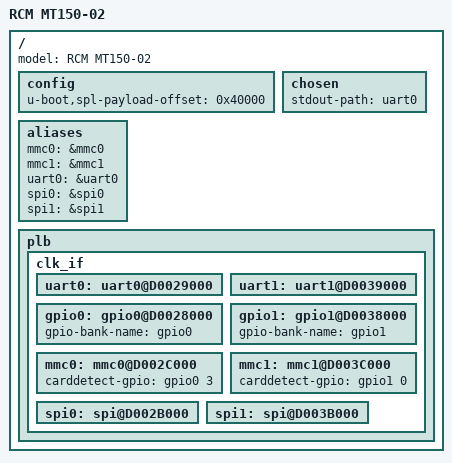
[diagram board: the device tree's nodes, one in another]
/*
 * Device Tree Source for RCM MT150.02 board
 *
 * Copyright (C) 2020 MIR
 *	Mikhail.Petrov@mir.dev
 *
 * SPDX-License-Identifier: GPL-2.0+
 */

#include "1888bm018.dtsi"

/ {
	model = "RCM MT150-02";

	config {
		u-boot,spl-payload-offset = <0x40000>;
	};

	chosen {
		stdout-path = "uart0";
	};

	aliases {
		mmc0 = &mmc0;
		mmc1 = &mmc1;
		uart0 = &uart0;
		spi0 = &spi0;
		spi1 = &spi1;
	};

	plb {
		clk_if {
			// console
			uart0: uart0@D0029000 {
				status = "okay";
			};

			uart1: uart1@D0039000 {
				status = "okay";
			};

			gpio0: gpio0@D0028000 {
				status = "okay";
				gpio-bank-name = "gpio0";
			};

			gpio1: gpio1@D0038000 {
				status = "okay";
				gpio-bank-name = "gpio1";
			};

			mmc0: mmc0@D002C000 {
				status = "okay";
				carddetect-gpio = <&gpio0 3 0>;
			};

			mmc1: mmc1@D003C000 {
				// status = "okay";
				carddetect-gpio = <&gpio1 0 0>;
			};

			spi0: spi@D002B000 {
				// status = "okay";
			};

			spi1: spi@D003B000 {
				// status = "okay";
			};
		};
	};
};

// Ethernet
#include "mt150-03.dtsi"

// NOR
// #include "mt150-04.dtsi"

// SRAM
// #include "mt150-07.dtsi"

// SDRAM
#include "mt150-08.dtsi"
